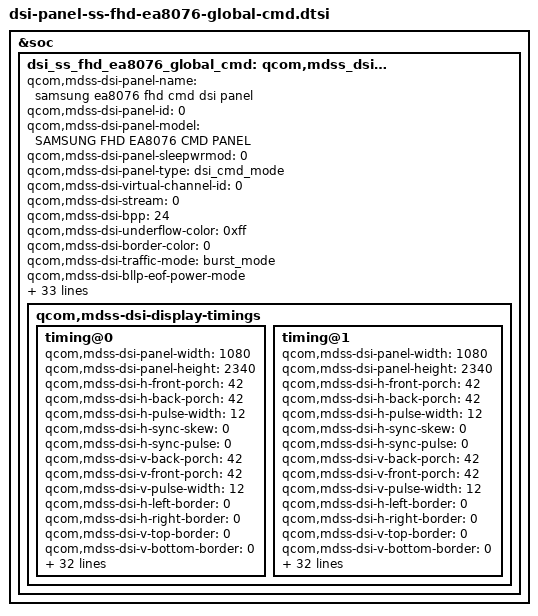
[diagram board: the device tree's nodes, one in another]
/* Copyright (c) 2015, The Linux Foundation. All rights reserved.
 *
 * This program is free software; you can redistribute it and/or modify
 * it under the terms of the GNU General Public License version 2 and
 * only version 2 as published by the Free Software Foundation.
 *
 * This program is distributed in the hope that it will be useful,
 * but WITHOUT ANY WARRANTY; without even the implied warranty of
 * MERCHANTABILITY or FITNESS FOR A PARTICULAR PURPOSE.  See the
 * GNU General Public License for more details.
 */

/*---------------------------------------------------------------------------
 * This file is autogenerated file using gcdb parser. Please do not edit it.
 * Update input XML file to add a new entry or update variable in this file
 * VERSION = "1.0"
 *---------------------------------------------------------------------------*/
&soc {
	dsi_ss_fhd_ea8076_global_cmd: qcom,mdss_dsi_ss_fhd_ea8076_global_cmd {
		qcom,mdss-dsi-panel-name = "samsung ea8076 fhd cmd dsi panel";
		qcom,mdss-dsi-panel-id = <0>;
		qcom,mdss-dsi-panel-model = "SAMSUNG FHD EA8076 CMD PANEL";
		qcom,mdss-dsi-panel-sleepwrmod = <0>;
		qcom,mdss-dsi-panel-type = "dsi_cmd_mode";
		qcom,mdss-dsi-virtual-channel-id = <0>;
		qcom,mdss-dsi-stream = <0>;
		qcom,mdss-dsi-bpp = <24>;
		qcom,mdss-dsi-underflow-color = <0xff>;
		qcom,mdss-dsi-border-color = <0>;
		qcom,mdss-dsi-traffic-mode = "burst_mode";
		qcom,mdss-dsi-bllp-eof-power-mode;
		qcom,mdss-dsi-bllp-power-mode;
		qcom,ulps-enabled;
		qcom,mdss-dsi-lp11-init;
		qcom,mdss-dsi-init-delay-us = <5000>;
		qcom,mdss-dsi-lane-0-state;
		qcom,mdss-dsi-lane-1-state;
		qcom,mdss-dsi-lane-2-state;
		qcom,mdss-dsi-lane-3-state;
		qcom,mdss-brightness-max-level = <4095>;
		qcom,bl-update-flag = "delay_until_first_frame";
		qcom,mdss-dsi-dma-trigger = "trigger_sw";
		qcom,mdss-dsi-mdp-trigger = "none";
		qcom,mdss-dsi-bl-dcs-type-ss;
		qcom,mdss-dsi-reset-sequence = <0 1>, <1 10>;
		qcom,mdss-pan-physical-width-dimension = <68>;
		qcom,mdss-pan-physical-height-dimension = <147>;
		qcom,mdss-dsi-te-pin-select = <1>;
		qcom,mdss-dsi-wr-mem-start = <0x2c>;
		qcom,mdss-dsi-wr-mem-continue = <0x3c>;
		qcom,mdss-dsi-te-dcs-command = <1>;
		qcom,mdss-dsi-te-check-enable;
		qcom,mdss-dsi-te-using-te-pin;
		qcom,mdss-dsi-tx-eot-append;
		qcom,mdss-dsi-panel-hdr-enabled;
		qcom,mdss-dsi-panel-hdr-color-primaries = <14500 15500 32000
			17000 15500 30000 8000 3000>;
		qcom,mdss-dsi-panel-peak-brightness = <4300000>;
		qcom,mdss-dsi-panel-blackness-level = <3230>;

		qcom,disp-fod-off-dimming-delay = <85>;
		qcom,disp-fod-dim-lut = <
			/* brightness, alpha */
			1 239
			9 233
			21 226
			42 216
			63 208
			83 202
			104 197
			125 191
			145 187
			166 184
			187 180
			207 175
			228 173
			267 166
			356 153
			445 143
			534 132
			623 126
			712 117
			801 110
			890 102
			979 95
			1068 89
			1157 83
			1246 77
			1335 72
			1424 66
			1513 61
			1602 55
			1691 50
			1780 45
			1869 41
			1958 35
			2047 31
		>;
		qcom,disp-dc-dim-lut = <
			/* brightness, alpha */
			1 205
			23 191
			45 164
			67 145
			89 130
			111 122
			133 109
			155 97
			177 85
			199 76
			221 67
			243 60
			265 51
			287 42
			309 34
			331 27
			353 22
			375 16
			397 7
			420 0
		>;

		qcom,mdss-dsi-display-timings {
			timing@0{
				qcom,mdss-dsi-panel-width = <1080>;
				qcom,mdss-dsi-panel-height = <2340>;
				qcom,mdss-dsi-h-front-porch = <42>;
				qcom,mdss-dsi-h-back-porch = <42>;
				qcom,mdss-dsi-h-pulse-width = <12>;
				qcom,mdss-dsi-h-sync-skew = <0>;
				qcom,mdss-dsi-h-sync-pulse = <0>;
				qcom,mdss-dsi-v-back-porch = <42>;
				qcom,mdss-dsi-v-front-porch = <42>;
				qcom,mdss-dsi-v-pulse-width = <12>;
				qcom,mdss-dsi-h-left-border = <0>;
				qcom,mdss-dsi-h-right-border = <0>;
				qcom,mdss-dsi-v-top-border = <0>;
				qcom,mdss-dsi-v-bottom-border = <0>;
				qcom,mdss-dsi-panel-framerate = <60>;
				qcom,mdss-dsi-panel-clockrate = <1103000000>;
				qcom,mdss-dsi-panel-jitter = <0x5 0x1>;
				qcom,mdss-dsi-on-command = [
					/* Sleep Out (Wait 10ms: 0x0A) */
					05 01 00 00 0A 00 02 11 00
					/* Test Key Enable: F0 */
					39 00 00 00 00 00 03 F0 5A 5A
					/* TE OUT(Vsync On) */
					39 00 00 00 00 00 02 35 00
					/* DBV Smooth Transition */
					39 00 00 00 00 00 03 B7 01 4B
					/* Test Key Disable: F0 */
					39 01 00 00 00 00 03 F0 A5 A5
					/* Page Address Set */
					39 01 00 00 00 00 05 2B 00 00 09 23
					/* Test Key Enable: F0 */
					39 00 00 00 00 00 03 F0 5A 5A
					/* Test Key Enable: FC */
					39 00 00 00 00 00 03 FC 5A 5A
					/* Set DDIC internal HFP */
					39 00 00 00 00 00 02 B0 23
					39 00 00 00 00 00 02 D1 11
					/* FFC Setting: MIPI Speed 82.6Mhz */
					39 00 00 00 00 00 0C E9 11 55 A6 75 A3 B9 A1 4A 00 1A B8
					/* Err_FG Setting */
					39 00 00 00 00 00 07 E1 00 00 02 02 42 02
					39 00 00 00 00 00 07 E2 00 00 00 00 00 00
					39 00 00 00 00 00 02 B0 0C
					39 00 00 00 00 00 02 E1 19
					/* Test Key Disable: F0 */
					39 00 00 00 00 00 03 F0 A5 A5
					/* Test Key Disable: FC */
					39 01 00 00 00 00 03 FC A5 A5
					/* Brightness Control */
					/* HBM Off */
					39 00 00 00 00 00 02 53 20
					/* Brightness Setting */
					39 00 00 00 00 00 03 51 00 00
					/* ACL OFF */
					39 01 00 00 43 00 02 55 00
					/* Display On (29h) */
					05 01 00 00 00 00 02 29 00
				];
				qcom,mdss-dsi-timing-switch-command = [39 00 00 00 00 00 03 f0 5a 5a 39 00 00 00 00 00 03 fc 5a 5a 39 00 00 00 00 00 02 b0 23 39 00 00 00 00 00 02 d1 0f 39 00 00 00 00 00 0c e9 11 55 a6 75 a3 b9 a1 4a 00 8a 18 39 00 00 00 00 00 03 f0 a5 a5 39 01 00 00 00 00 03 fc a5 a5];
				qcom,mdss-dsi-timing-switch-command-state = "dsi_lp_mode";
				qcom,mdss-dsi-off-command = [
					/* Display Off */
					05 01 00 00 00 00 02 28 00
					/* Sleep In */
					05 01 00 00 78 00 02 10 00
				];
				qcom,mdss-dsi-on-command-state = "dsi_lp_mode";
				qcom,mdss-dsi-off-command-state = "dsi_lp_mode";

				qcom,mdss-dsi-nolp-command = [
					/* Display Off (Wait 16ms: 0x10) */
					05 01 00 00 10 00 02 28 00
					/* HBM off + Disable brightness dimming */
					39 01 00 00 00 00 02 53 20
					/* Display on (29h) */
					05 01 00 00 00 00 02 29 00
				];
				qcom,mdss-dsi-nolp-command-state = "dsi_lp_mode";

				qcom,mdss-dsi-dispparam-hbm-off-command = [39 01 00 00 00 00 02 53 28];
				qcom,mdss-dsi-dispparam-hbm-off-command-state = "dsi_lp_mode";
				qcom,mdss-dsi-dispparam-hbm-on-command = [39 01 00 00 00 00 02 53 E8];
				qcom,mdss-dsi-dispparam-hbm-on-command-state = "dsi_lp_mode";

				qcom,mdss-dsi-dispparam-hbm-fod-off-command = [
					/* HBM off + Disable brightness dimming */
					15 01 00 00 10 00 02 53 20
				];
				qcom,mdss-dsi-dispparam-hbm-fod-off-command-state = "dsi_hs_mode";
				qcom,mdss-dsi-dispparam-hbm-fod-on-command = [
					/* Test Key Enable: F0 */
					39 00 00 00 00 00 03 F0 5A 5A
					/* Elvss Dimming Setting */
					15 00 00 00 00 00 02 B0 03
					15 00 00 00 00 00 02 B7 C9
					/* Test Key Disable: F0 */
					39 00 00 00 00 00 03 F0 A5 A5
					/* HBM on + Disable brightness dimming */
					15 01 00 00 10 00 02 53 E0
				];
				qcom,mdss-dsi-dispparam-hbm-fod-on-command-state = "dsi_hs_mode";
			};
			timing@1{
				qcom,mdss-dsi-panel-width = <1080>;
				qcom,mdss-dsi-panel-height = <2340>;
				qcom,mdss-dsi-h-front-porch = <42>;
				qcom,mdss-dsi-h-back-porch = <42>;
				qcom,mdss-dsi-h-pulse-width = <12>;
				qcom,mdss-dsi-h-sync-skew = <0>;
				qcom,mdss-dsi-h-sync-pulse = <0>;
				qcom,mdss-dsi-v-back-porch = <42>;
				qcom,mdss-dsi-v-front-porch = <42>;
				qcom,mdss-dsi-v-pulse-width = <12>;
				qcom,mdss-dsi-h-left-border = <0>;
				qcom,mdss-dsi-h-right-border = <0>;
				qcom,mdss-dsi-v-top-border = <0>;
				qcom,mdss-dsi-v-bottom-border = <0>;
				qcom,mdss-dsi-panel-framerate = <90>;
				qcom,mdss-dsi-panel-clockrate = "Yh/";
				qcom,mdss-dsi-panel-jitter = <0x5 0x1>;
				qcom,mdss-dsi-on-command = [
					/* Sleep Out (Wait 10ms: 0x0A) */
					05 01 00 00 0A 00 02 11 00
					/* Test Key Enable: F0 */
					39 00 00 00 00 00 03 F0 5A 5A
					/* TE OUT(Vsync On) */
					39 00 00 00 00 00 02 35 00
					/* DBV Smooth Transition */
					39 00 00 00 00 00 03 B7 01 4B
					/* Test Key Disable: F0 */
					39 01 00 00 00 00 03 F0 A5 A5
					/* Page Address Set */
					39 01 00 00 00 00 05 2B 00 00 09 23
					/* Test Key Enable: F0 */
					39 00 00 00 00 00 03 F0 5A 5A
					/* Test Key Enable: FC */
					39 00 00 00 00 00 03 FC 5A 5A
					/* Set DDIC internal HFP */
					39 00 00 00 00 00 02 B0 23
					39 00 00 00 00 00 02 D1 11
					/* FFC Setting: MIPI Speed 82.6Mhz */
					39 00 00 00 00 00 0C E9 11 55 A6 75 A3 B9 A1 4A 00 1A B8
					/* Err_FG Setting */
					39 00 00 00 00 00 07 E1 00 00 02 02 42 02
					39 00 00 00 00 00 07 E2 00 00 00 00 00 00
					39 00 00 00 00 00 02 B0 0C
					39 00 00 00 00 00 02 E1 19
					/* Test Key Disable: F0 */
					39 00 00 00 00 00 03 F0 A5 A5
					/* Test Key Disable: FC */
					39 01 00 00 00 00 03 FC A5 A5
					/* Brightness Control */
					/* HBM Off */
					39 00 00 00 00 00 02 53 20
					/* Brightness Setting */
					39 00 00 00 00 00 03 51 00 00
					/* ACL OFF */
					39 01 00 00 43 00 02 55 00
					/* Display On (29h) */
					05 01 00 00 00 00 02 29 00
				];
				qcom,mdss-dsi-timing-switch-command = [39 00 00 00 00 00 03 f0 5a 5a 39 00 00 00 00 00 03 fc 5a 5a 39 00 00 00 00 00 02 b0 23 39 00 00 00 00 00 02 d1 0f 39 00 00 00 00 00 0c e9 11 55 a6 75 a3 a9 a1 4a 00 8a 18 39 00 00 00 00 00 03 f0 a5 a5 39 01 00 00 00 00 03 fc a5 a5];
				qcom,mdss-dsi-timing-switch-command-state = "dsi_lp_mode";
				qcom,mdss-dsi-off-command = [
					/* Display Off */
					05 01 00 00 00 00 02 28 00
					/* Sleep In */
					05 01 00 00 78 00 02 10 00
				];
				qcom,mdss-dsi-on-command-state = "dsi_lp_mode";
				qcom,mdss-dsi-off-command-state = "dsi_lp_mode";

				qcom,mdss-dsi-nolp-command = [
					/* Display Off (Wait 16ms: 0x10) */
					05 01 00 00 10 00 02 28 00
					/* HBM off + Disable brightness dimming */
					39 01 00 00 00 00 02 53 20
					/* Display on (29h) */
					05 01 00 00 00 00 02 29 00
				];
				qcom,mdss-dsi-nolp-command-state = "dsi_lp_mode";

				qcom,mdss-dsi-dispparam-hbm-off-command = [39 01 00 00 00 00 02 53 28];
				qcom,mdss-dsi-dispparam-hbm-off-command-state = "dsi_lp_mode";
				qcom,mdss-dsi-dispparam-hbm-on-command = [39 01 00 00 00 00 02 53 E8];
				qcom,mdss-dsi-dispparam-hbm-on-command-state = "dsi_lp_mode";

				qcom,mdss-dsi-dispparam-hbm-fod-off-command = [
					/* HBM off + Disable brightness dimming */
					15 01 00 00 10 00 02 53 20
				];
				qcom,mdss-dsi-dispparam-hbm-fod-off-command-state = "dsi_hs_mode";
				qcom,mdss-dsi-dispparam-hbm-fod-on-command = [
					/* Test Key Enable: F0 */
					39 00 00 00 00 00 03 F0 5A 5A
					/* Elvss Dimming Setting */
					15 00 00 00 00 00 02 B0 03
					15 00 00 00 00 00 02 B7 C9
					/* Test Key Disable: F0 */
					39 00 00 00 00 00 03 F0 A5 A5
					/* HBM on + Disable brightness dimming */
					15 01 00 00 10 00 02 53 E0
				];
				qcom,mdss-dsi-dispparam-hbm-fod-on-command-state = "dsi_hs_mode";
			};
		};
	};
};
